VERSION ""

NS_ :

BS_:

BU_:

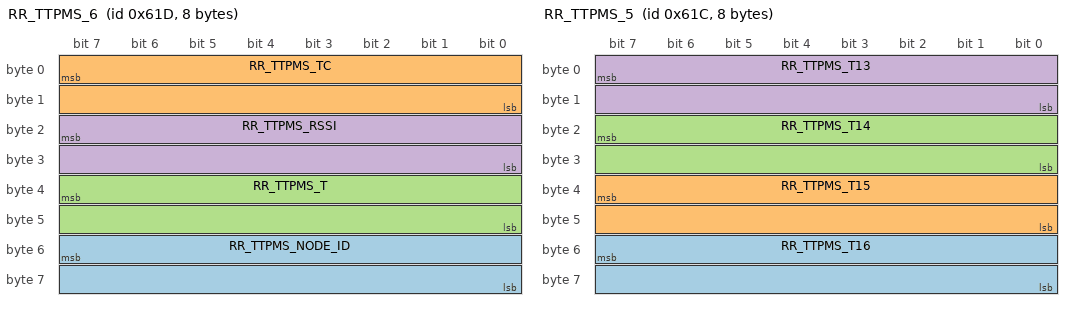
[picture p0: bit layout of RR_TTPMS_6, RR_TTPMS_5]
BO_ 1565 RR_TTPMS_6: 8 Vector__XXX
 SG_ RR_TTPMS_NODE_ID : 55|16@0+ (1,0) [0|65535] "" Vector__XXX
 SG_ RR_TTPMS_TC : 7|16@0+ (1,0) [0|65535] "" Vector__XXX
 SG_ RR_TTPMS_T : 39|16@0+ (0.1,-100) [-100|6453.5] "°C" Vector__XXX
 SG_ RR_TTPMS_RSSI : 23|16@0- (1,0) [-32768|32767] "dBm" Vector__XXX

BO_ 1564 RR_TTPMS_5: 8 Vector__XXX
 SG_ RR_TTPMS_T16 : 55|16@0+ (0.1,-100) [-100|6453.5] "°C" Vector__XXX
 SG_ RR_TTPMS_T15 : 39|16@0+ (0.1,-100) [-100|6453.5] "°C" Vector__XXX
 SG_ RR_TTPMS_T14 : 23|16@0+ (0.1,-100) [-100|6453.5] "°C" Vector__XXX
 SG_ RR_TTPMS_T13 : 7|16@0+ (0.1,-100) [-100|6453.5] "°C" Vector__XXX

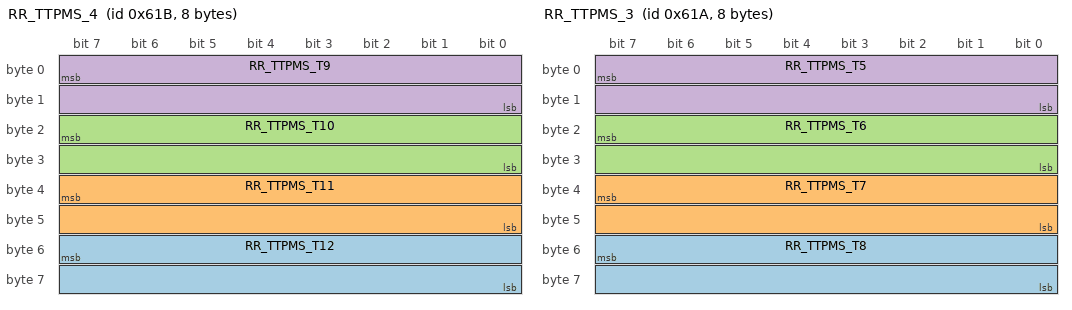
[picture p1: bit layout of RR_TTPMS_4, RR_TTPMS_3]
BO_ 1563 RR_TTPMS_4: 8 Vector__XXX
 SG_ RR_TTPMS_T12 : 55|16@0+ (0.1,-100) [-100|6453.5] "°C" Vector__XXX
 SG_ RR_TTPMS_T11 : 39|16@0+ (0.1,-100) [-100|6453.5] "°C" Vector__XXX
 SG_ RR_TTPMS_T10 : 23|16@0+ (0.1,-100) [-100|6453.5] "°C" Vector__XXX
 SG_ RR_TTPMS_T9 : 7|16@0+ (0.1,-100) [-100|6453.5] "°C" Vector__XXX

BO_ 1562 RR_TTPMS_3: 8 Vector__XXX
 SG_ RR_TTPMS_T8 : 55|16@0+ (0.1,-100) [-100|6453.5] "°C" Vector__XXX
 SG_ RR_TTPMS_T7 : 39|16@0+ (0.1,-100) [-100|6453.5] "°C" Vector__XXX
 SG_ RR_TTPMS_T6 : 23|16@0+ (0.1,-100) [-100|6453.5] "°C" Vector__XXX
 SG_ RR_TTPMS_T5 : 7|16@0+ (0.1,-100) [-100|6453.5] "°C" Vector__XXX

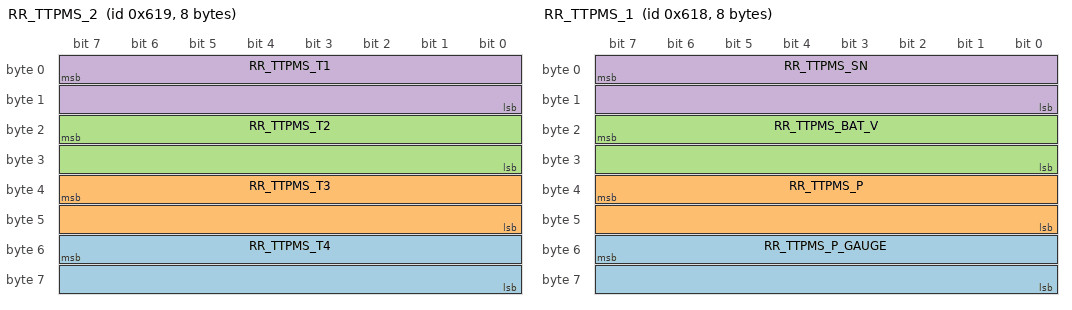
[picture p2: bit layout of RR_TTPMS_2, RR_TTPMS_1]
BO_ 1561 RR_TTPMS_2: 8 Vector__XXX
 SG_ RR_TTPMS_T4 : 55|16@0+ (0.1,-100) [-100|6453.5] "°C" Vector__XXX
 SG_ RR_TTPMS_T3 : 39|16@0+ (0.1,-100) [-100|6453.5] "°C" Vector__XXX
 SG_ RR_TTPMS_T2 : 23|16@0+ (0.1,-100) [-100|6453.5] "°C" Vector__XXX
 SG_ RR_TTPMS_T1 : 7|16@0+ (0.1,-100) [-100|6453.5] "°C" Vector__XXX

BO_ 1560 RR_TTPMS_1: 8 Vector__XXX
 SG_ RR_TTPMS_P_GAUGE : 55|16@0+ (1,0) [0|65535] "mbar" Vector__XXX
 SG_ RR_TTPMS_P : 39|16@0+ (1,0) [0|65535] "mbar" Vector__XXX
 SG_ RR_TTPMS_BAT_V : 23|16@0+ (1,0) [0|65535] "mV" Vector__XXX
 SG_ RR_TTPMS_SN : 7|16@0+ (1,0) [0|65535] "" Vector__XXX

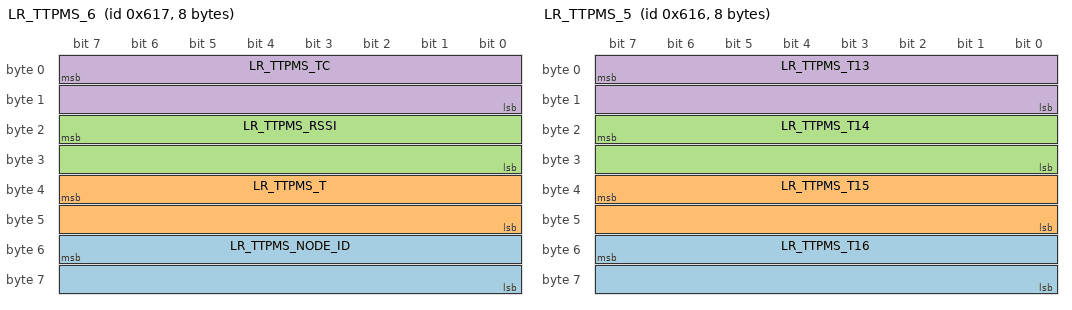
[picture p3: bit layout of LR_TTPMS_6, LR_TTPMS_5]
BO_ 1559 LR_TTPMS_6: 8 Vector__XXX
 SG_ LR_TTPMS_NODE_ID : 55|16@0+ (1,0) [0|65535] "" Vector__XXX
 SG_ LR_TTPMS_T : 39|16@0+ (0.1,-100) [-100|6453.5] "°C" Vector__XXX
 SG_ LR_TTPMS_RSSI : 23|16@0- (1,0) [-32768|32767] "dBm" Vector__XXX
 SG_ LR_TTPMS_TC : 7|16@0+ (1,0) [0|65535] "" Vector__XXX

BO_ 1558 LR_TTPMS_5: 8 Vector__XXX
 SG_ LR_TTPMS_T16 : 55|16@0+ (0.1,-100) [-100|6453.5] "°C" Vector__XXX
 SG_ LR_TTPMS_T15 : 39|16@0+ (0.1,-100) [-100|6453.5] "°C" Vector__XXX
 SG_ LR_TTPMS_T14 : 23|16@0+ (0.1,-100) [-100|6453.5] "°C" Vector__XXX
 SG_ LR_TTPMS_T13 : 7|16@0+ (0.1,-100) [-100|6453.5] "°C" Vector__XXX

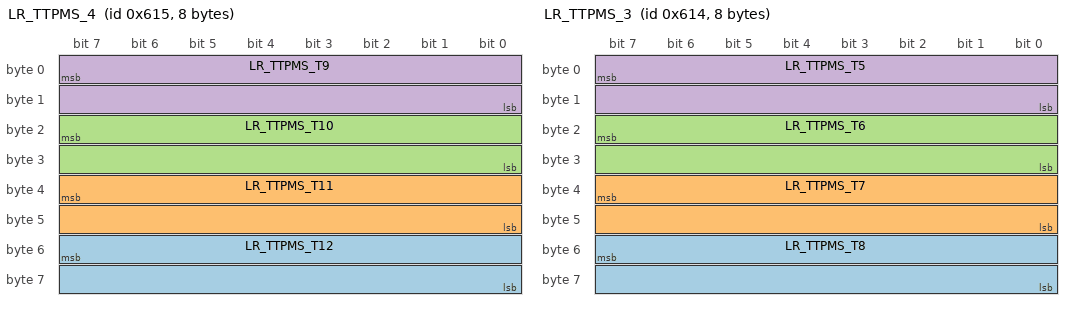
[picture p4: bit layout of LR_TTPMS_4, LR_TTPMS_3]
BO_ 1557 LR_TTPMS_4: 8 Vector__XXX
 SG_ LR_TTPMS_T12 : 55|16@0+ (0.1,-100) [-100|6453.5] "°C" Vector__XXX
 SG_ LR_TTPMS_T11 : 39|16@0+ (0.1,-100) [-100|6453.5] "°C" Vector__XXX
 SG_ LR_TTPMS_T10 : 23|16@0+ (0.1,-100) [-100|6453.5] "°C" Vector__XXX
 SG_ LR_TTPMS_T9 : 7|16@0+ (0.1,-100) [-100|6453.5] "°C" Vector__XXX

BO_ 1556 LR_TTPMS_3: 8 Vector__XXX
 SG_ LR_TTPMS_T8 : 55|16@0+ (0.1,-100) [-100|6453.5] "°C" Vector__XXX
 SG_ LR_TTPMS_T7 : 39|16@0+ (0.1,-100) [-100|6453.5] "°C" Vector__XXX
 SG_ LR_TTPMS_T6 : 23|16@0+ (0.1,-100) [-100|6453.5] "°C" Vector__XXX
 SG_ LR_TTPMS_T5 : 7|16@0+ (0.1,-100) [-100|6453.5] "°C" Vector__XXX

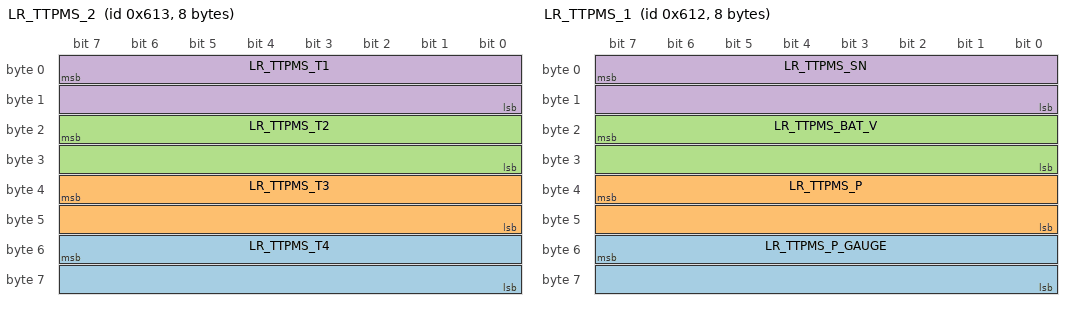
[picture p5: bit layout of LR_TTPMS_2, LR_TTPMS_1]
BO_ 1555 LR_TTPMS_2: 8 Vector__XXX
 SG_ LR_TTPMS_T4 : 55|16@0+ (0.1,-100) [-100|6453.5] "°C" Vector__XXX
 SG_ LR_TTPMS_T3 : 39|16@0+ (0.1,-100) [-100|6453.5] "°C" Vector__XXX
 SG_ LR_TTPMS_T2 : 23|16@0+ (0.1,-100) [-100|6453.5] "°C" Vector__XXX
 SG_ LR_TTPMS_T1 : 7|16@0+ (0.1,-100) [-100|6453.5] "°C" Vector__XXX

BO_ 1554 LR_TTPMS_1: 8 Vector__XXX
 SG_ LR_TTPMS_P_GAUGE : 55|16@0+ (1,0) [0|65535] "mbar" Vector__XXX
 SG_ LR_TTPMS_P : 39|16@0+ (1,0) [0|65535] "mbar" Vector__XXX
 SG_ LR_TTPMS_BAT_V : 23|16@0+ (1,0) [0|65535] "mV" Vector__XXX
 SG_ LR_TTPMS_SN : 7|16@0+ (1,0) [0|65535] "" Vector__XXX

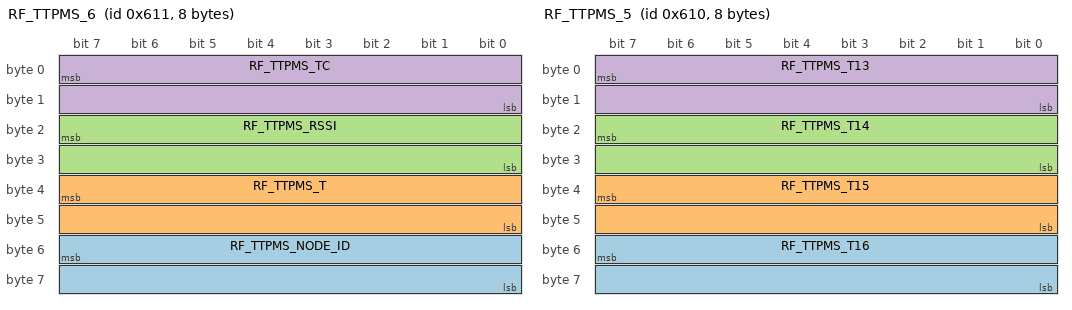
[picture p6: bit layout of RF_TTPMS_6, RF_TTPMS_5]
BO_ 1553 RF_TTPMS_6: 8 Vector__XXX
 SG_ RF_TTPMS_NODE_ID : 55|16@0+ (1,0) [0|65535] "" Vector__XXX
 SG_ RF_TTPMS_T : 39|16@0+ (0.1,-100) [-100|6453.5] "°C" Vector__XXX
 SG_ RF_TTPMS_RSSI : 23|16@0- (1,0) [-32768|32767] "dBm" Vector__XXX
 SG_ RF_TTPMS_TC : 7|16@0+ (1,0) [0|65535] "" Vector__XXX

BO_ 1552 RF_TTPMS_5: 8 Vector__XXX
 SG_ RF_TTPMS_T16 : 55|16@0+ (0.1,-100) [-100|6453.5] "°C" Vector__XXX
 SG_ RF_TTPMS_T15 : 39|16@0+ (0.1,-100) [-100|6453.5] "°C" Vector__XXX
 SG_ RF_TTPMS_T14 : 23|16@0+ (0.1,-100) [-100|6453.5] "°C" Vector__XXX
 SG_ RF_TTPMS_T13 : 7|16@0+ (0.1,-100) [-100|6453.5] "°C" Vector__XXX

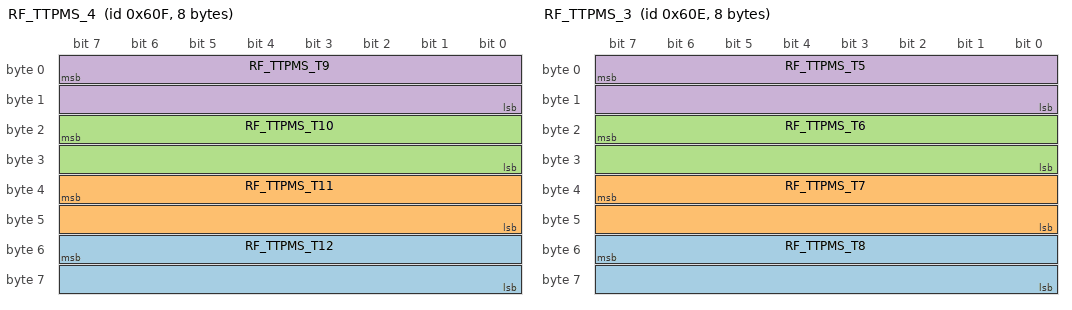
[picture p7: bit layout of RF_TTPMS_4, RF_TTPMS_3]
BO_ 1551 RF_TTPMS_4: 8 Vector__XXX
 SG_ RF_TTPMS_T12 : 55|16@0+ (0.1,-100) [-100|6453.5] "°C" Vector__XXX
 SG_ RF_TTPMS_T11 : 39|16@0+ (0.1,-100) [-100|6453.5] "°C" Vector__XXX
 SG_ RF_TTPMS_T10 : 23|16@0+ (0.1,-100) [-100|6453.5] "°C" Vector__XXX
 SG_ RF_TTPMS_T9 : 7|16@0+ (0.1,-100) [-100|6453.5] "°C" Vector__XXX

BO_ 1550 RF_TTPMS_3: 8 Vector__XXX
 SG_ RF_TTPMS_T8 : 55|16@0+ (0.1,-100) [-100|6453.5] "°C" Vector__XXX
 SG_ RF_TTPMS_T7 : 39|16@0+ (0.1,-100) [-100|6453.5] "°C" Vector__XXX
 SG_ RF_TTPMS_T6 : 23|16@0+ (0.1,-100) [-100|6453.5] "°C" Vector__XXX
 SG_ RF_TTPMS_T5 : 7|16@0+ (0.1,-100) [-100|6453.5] "°C" Vector__XXX

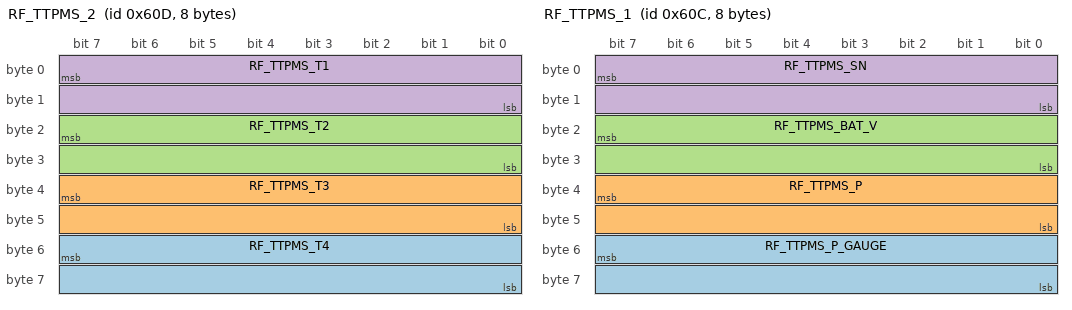
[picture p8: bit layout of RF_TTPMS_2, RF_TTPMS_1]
BO_ 1549 RF_TTPMS_2: 8 Vector__XXX
 SG_ RF_TTPMS_T4 : 55|16@0+ (0.1,-100) [-100|6453.5] "°C" Vector__XXX
 SG_ RF_TTPMS_T3 : 39|16@0+ (0.1,-100) [-100|6453.5] "°C" Vector__XXX
 SG_ RF_TTPMS_T2 : 23|16@0+ (0.1,-100) [-100|6453.5] "°C" Vector__XXX
 SG_ RF_TTPMS_T1 : 7|16@0+ (0.1,-100) [-100|6453.5] "°C" Vector__XXX

BO_ 1548 RF_TTPMS_1: 8 Vector__XXX
 SG_ RF_TTPMS_P_GAUGE : 55|16@0+ (1,0) [0|65535] "mbar" Vector__XXX
 SG_ RF_TTPMS_P : 39|16@0+ (1,0) [0|65535] "mbar" Vector__XXX
 SG_ RF_TTPMS_BAT_V : 23|16@0+ (1,0) [0|65535] "mV" Vector__XXX
 SG_ RF_TTPMS_SN : 7|16@0+ (1,0) [0|65535] "" Vector__XXX

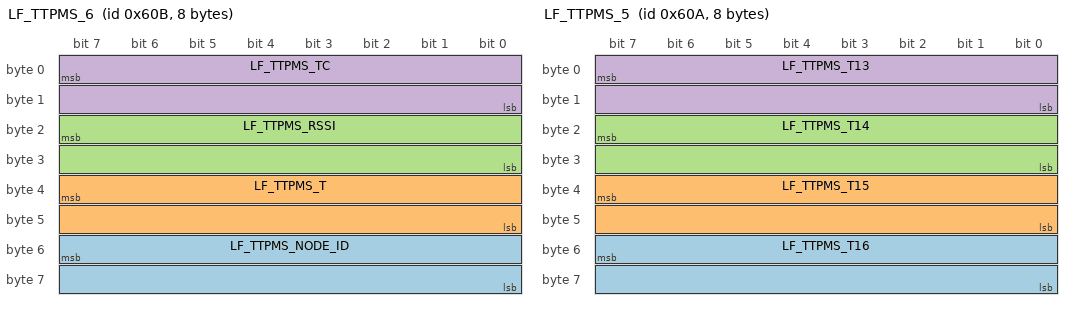
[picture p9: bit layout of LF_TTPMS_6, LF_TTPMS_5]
BO_ 1547 LF_TTPMS_6: 8 Vector__XXX
 SG_ LF_TTPMS_NODE_ID : 55|16@0+ (1,0) [0|65535] "" Vector__XXX
 SG_ LF_TTPMS_T : 39|16@0+ (0.1,-100) [-100|6453.5] "°C" Vector__XXX
 SG_ LF_TTPMS_RSSI : 23|16@0- (1,0) [-32768|32767] "dBm" Vector__XXX
 SG_ LF_TTPMS_TC : 7|16@0+ (1,0) [0|65535] "" Vector__XXX

BO_ 1546 LF_TTPMS_5: 8 Vector__XXX
 SG_ LF_TTPMS_T16 : 55|16@0+ (0.1,-100) [-100|6453.5] "°C" Vector__XXX
 SG_ LF_TTPMS_T15 : 39|16@0+ (0.1,-100) [-100|6453.5] "°C" Vector__XXX
 SG_ LF_TTPMS_T14 : 23|16@0+ (0.1,-100) [-100|6453.5] "°C" Vector__XXX
 SG_ LF_TTPMS_T13 : 7|16@0+ (0.1,-100) [-100|6453.5] "°C" Vector__XXX

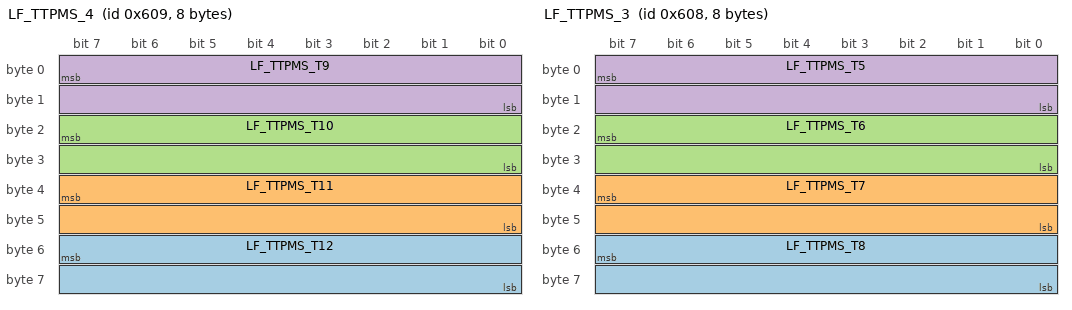
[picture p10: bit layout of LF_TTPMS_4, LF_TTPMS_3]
BO_ 1545 LF_TTPMS_4: 8 Vector__XXX
 SG_ LF_TTPMS_T12 : 55|16@0+ (0.1,-100) [-100|6453.5] "°C" Vector__XXX
 SG_ LF_TTPMS_T11 : 39|16@0+ (0.1,-100) [-100|6453.5] "°C" Vector__XXX
 SG_ LF_TTPMS_T10 : 23|16@0+ (0.1,-100) [-100|6453.5] "°C" Vector__XXX
 SG_ LF_TTPMS_T9 : 7|16@0+ (0.1,-100) [-100|6453.5] "°C" Vector__XXX

BO_ 1544 LF_TTPMS_3: 8 Vector__XXX
 SG_ LF_TTPMS_T8 : 55|16@0+ (0.1,-100) [-100|6453.5] "°C" Vector__XXX
 SG_ LF_TTPMS_T7 : 39|16@0+ (0.1,-100) [-100|6453.5] "°C" Vector__XXX
 SG_ LF_TTPMS_T6 : 23|16@0+ (0.1,-100) [-100|6453.5] "°C" Vector__XXX
 SG_ LF_TTPMS_T5 : 7|16@0+ (0.1,-100) [-100|6453.5] "°C" Vector__XXX

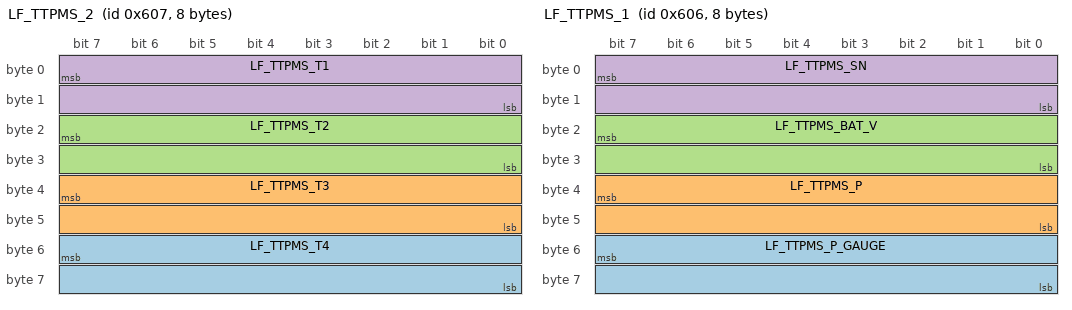
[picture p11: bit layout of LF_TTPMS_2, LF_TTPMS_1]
BO_ 1543 LF_TTPMS_2: 8 Vector__XXX
 SG_ LF_TTPMS_T4 : 55|16@0+ (0.1,-100) [-100|6453.5] "°C" Vector__XXX
 SG_ LF_TTPMS_T3 : 39|16@0+ (0.1,-100) [-100|6453.5] "°C" Vector__XXX
 SG_ LF_TTPMS_T2 : 23|16@0+ (0.1,-100) [-100|6453.5] "°C" Vector__XXX
 SG_ LF_TTPMS_T1 : 7|16@0+ (0.1,-100) [-100|6453.5] "°C" Vector__XXX

BO_ 1542 LF_TTPMS_1: 8 Vector__XXX
 SG_ LF_TTPMS_P_GAUGE : 55|16@0+ (1,0) [0|65535] "mbar" Vector__XXX
 SG_ LF_TTPMS_P : 39|16@0+ (1,0) [0|65535] "mbar" Vector__XXX
 SG_ LF_TTPMS_BAT_V : 23|16@0+ (1,0) [0|65535] "mV" Vector__XXX
 SG_ LF_TTPMS_SN : 7|16@0+ (1,0) [0|65535] "" Vector__XXX
